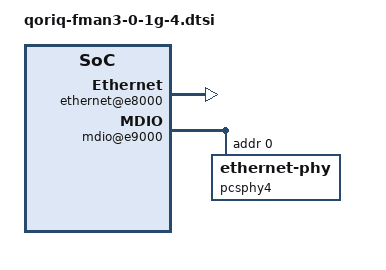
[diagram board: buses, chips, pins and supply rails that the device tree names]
/*
 * QorIQ FMan v3 1g port #4 device tree stub [ controller @ offset 0x400000 ]
 *
 * Copyright 2012 - 2015 Freescale Semiconductor Inc.
 *
 * Redistribution and use in source and binary forms, with or without
 * modification, are permitted provided that the following conditions are met:
 *     * Redistributions of source code must retain the above copyright
 *	 notice, this list of conditions and the following disclaimer.
 *     * Redistributions in binary form must reproduce the above copyright
 *	 notice, this list of conditions and the following disclaimer in the
 *	 documentation and/or other materials provided with the distribution.
 *     * Neither the name of Freescale Semiconductor nor the
 *	 names of its contributors may be used to endorse or promote products
 *	 derived from this software without specific prior written permission.
 *
 *
 * ALTERNATIVELY, this software may be distributed under the terms of the
 * GNU General Public License ("GPL") as published by the Free Software
 * Foundation, either version 2 of that License or (at your option) any
 * later version.
 *
 * THIS SOFTWARE IS PROVIDED BY Freescale Semiconductor ``AS IS'' AND ANY
 * EXPRESS OR IMPLIED WARRANTIES, INCLUDING, BUT NOT LIMITED TO, THE IMPLIED
 * WARRANTIES OF MERCHANTABILITY AND FITNESS FOR A PARTICULAR PURPOSE ARE
 * DISCLAIMED. IN NO EVENT SHALL Freescale Semiconductor BE LIABLE FOR ANY
 * DIRECT, INDIRECT, INCIDENTAL, SPECIAL, EXEMPLARY, OR CONSEQUENTIAL DAMAGES
 * (INCLUDING, BUT NOT LIMITED TO, PROCUREMENT OF SUBSTITUTE GOODS OR SERVICES;
 * LOSS OF USE, DATA, OR PROFITS; OR BUSINESS INTERRUPTION) HOWEVER CAUSED AND
 * ON ANY THEORY OF LIABILITY, WHETHER IN CONTRACT, STRICT LIABILITY, OR TORT
 * (INCLUDING NEGLIGENCE OR OTHERWISE) ARISING IN ANY WAY OUT OF THE USE OF THIS
 * SOFTWARE, EVEN IF ADVISED OF THE POSSIBILITY OF SUCH DAMAGE.
 */

fman@400000 {
	fman0_rx_0x0c: port@8c000 {
		cell-index = <0xc>;
		compatible = "fsl,fman-v3-port-rx";
		reg = <0x8c000 0x1000>;
	};

	fman0_tx_0x2c: port@ac000 {
		cell-index = <0x2c>;
		compatible = "fsl,fman-v3-port-tx";
		reg = <0xac000 0x1000>;
	};

	ethernet@e8000 {
		cell-index = <4>;
		compatible = "fsl,fman-memac";
		reg = <0xe8000 0x1000>;
		fsl,fman-ports = <&fman0_rx_0x0c &fman0_tx_0x2c>;
		ptp-timer = <&ptp_timer0>;
		pcsphy-handle = <&pcsphy4>;
	};

	mdio@e9000 {
		#address-cells = <1>;
		#size-cells = <0>;
		compatible = "fsl,fman-memac-mdio", "fsl,fman-xmdio";
		reg = <0xe9000 0x1000>;
		fsl,erratum-a011043; /* must ignore read errors */

		pcsphy4: ethernet-phy@0 {
			reg = <0x0>;
		};
	};
};
